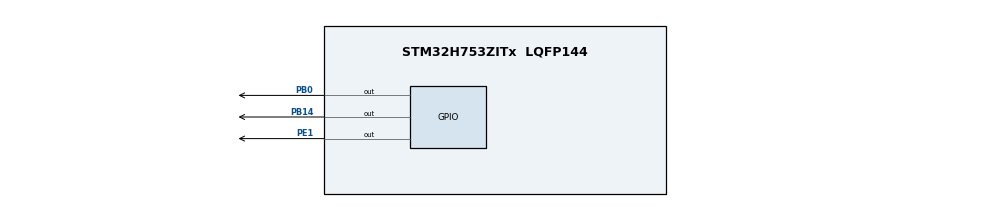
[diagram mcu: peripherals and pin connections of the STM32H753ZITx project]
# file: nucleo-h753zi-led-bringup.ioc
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CORTEX_M7.CPU_DCache=Disabled
CORTEX_M7.CPU_ICache=Disabled
CORTEX_M7.MPU_Control=__NULL
CORTEX_M7.default_mode_Activation=1
Mcu.Family=STM32H7
Mcu.Name=STM32H753ZITx
Mcu.Package=LQFP144
NVIC.PriorityGroup=NVIC_PRIORITYGROUP_4
PB0.Signal=GPIO_Output
PB14.Signal=GPIO_Output
PC14-OSC32_IN\ (OSC32_IN).Signal=RCC_OSC32_IN
PC15-OSC32_OUT\ (OSC32_OUT).Signal=RCC_OSC32_OUT
PD8.GPIO_Label=STLINK_RX
PD8.Signal=USART3_TX
PD9.GPIO_Label=STLINK_TX
PD9.Signal=USART3_RX
PE1.Signal=GPIO_Output
PH0-OSC_IN\ (PH0).Signal=RCC_OSC_IN
PH1-OSC_OUT\ (PH1).Signal=RCC_OSC_OUT
ProjectManager.HeapSize=0x200
ProjectManager.StackSize=0x400
ProjectManager.TargetToolchain=Makefile
RCC.ADCFreq_Value=129000000
RCC.APB1Freq_Value=64000000
RCC.APB2Freq_Value=64000000
RCC.APB3Freq_Value=64000000
RCC.APB4Freq_Value=64000000
RCC.CortexFreq_Value=64000000
RCC.DIVM1=1
RCC.DIVN1=24
RCC.DIVQ1=4
RCC.HCLKFreq_Value=64000000
RCC.HSE_VALUE=8000000
RCC.PLLFRACN=0
RCC.PWR_Regulator_Voltage_Scale=PWR_REGULATOR_VOLTAGE_SCALE2
RCC.SYSCLKFreq_VALUE=64000000
RCC.USBFreq_Value=384000000
board=NUCLEO-H753ZI

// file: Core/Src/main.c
/* USER CODE BEGIN Header */
/**
  ******************************************************************************
  * @file           : main.c
  * @brief          : Main program body
  ******************************************************************************
  * @attention
  *
  * Copyright (c) 2025 STMicroelectronics.
  * All rights reserved.
  *
  * This software is licensed under terms that can be found in the LICENSE file
  * in the root directory of this software component.
  * If no LICENSE file comes with this software, it is provided AS-IS.
  *
  ******************************************************************************
  */
/* USER CODE END Header */
#include "main.h"

void SystemClock_Config(void);
static void MX_GPIO_Init(void);

int main(void)
{

  /* MCU Configuration--------------------------------------------------------*/

  /* Reset of all peripherals, Initializes the Flash interface and the Systick. */
  HAL_Init();

  /* Configure the system clock */
  SystemClock_Config();

  /* Initialize all configured peripherals */
  MX_GPIO_Init();
  /* USER CODE BEGIN 2 */
  HAL_GPIO_WritePin(GPIOB, GPIO_PIN_0 | GPIO_PIN_14, GPIO_PIN_SET);
  HAL_GPIO_WritePin(GPIOE, GPIO_PIN_1, GPIO_PIN_SET);
  /* USER CODE END 2 */

  /* Infinite loop */
  while (1)
  {

  }
}

void SystemClock_Config(void)
{
  RCC_OscInitTypeDef RCC_OscInitStruct = {0};
  RCC_ClkInitTypeDef RCC_ClkInitStruct = {0};

  /** Supply configuration update enable
  */
  HAL_PWREx_ConfigSupply(PWR_LDO_SUPPLY);

  /** Configure the main internal regulator output voltage
  */
  __HAL_PWR_VOLTAGESCALING_CONFIG(PWR_REGULATOR_VOLTAGE_SCALE2);

  while(!__HAL_PWR_GET_FLAG(PWR_FLAG_VOSRDY)) {}

  /** Initializes the RCC Oscillators according to the specified parameters
  * in the RCC_OscInitTypeDef structure.
  */
  RCC_OscInitStruct.OscillatorType = RCC_OSCILLATORTYPE_HSI;
  RCC_OscInitStruct.HSIState = RCC_HSI_DIV1;
  RCC_OscInitStruct.HSICalibrationValue = RCC_HSICALIBRATION_DEFAULT;
  RCC_OscInitStruct.PLL.PLLState = RCC_PLL_NONE;
  if (HAL_RCC_OscConfig(&RCC_OscInitStruct) != HAL_OK)
  {
    Error_Handler();
  }

  /** Initializes the CPU, AHB and APB buses clocks
  */
  RCC_ClkInitStruct.ClockType = RCC_CLOCKTYPE_HCLK|RCC_CLOCKTYPE_SYSCLK
                              |RCC_CLOCKTYPE_PCLK1|RCC_CLOCKTYPE_PCLK2
                              |RCC_CLOCKTYPE_D3PCLK1|RCC_CLOCKTYPE_D1PCLK1;
  RCC_ClkInitStruct.SYSCLKSource = RCC_SYSCLKSOURCE_HSI;
  RCC_ClkInitStruct.SYSCLKDivider = RCC_SYSCLK_DIV1;
  RCC_ClkInitStruct.AHBCLKDivider = RCC_HCLK_DIV1;
  RCC_ClkInitStruct.APB3CLKDivider = RCC_APB3_DIV1;
  RCC_ClkInitStruct.APB1CLKDivider = RCC_APB1_DIV1;
  RCC_ClkInitStruct.APB2CLKDivider = RCC_APB2_DIV1;
  RCC_ClkInitStruct.APB4CLKDivider = RCC_APB4_DIV1;

  if (HAL_RCC_ClockConfig(&RCC_ClkInitStruct, FLASH_LATENCY_1) != HAL_OK)
  {
    Error_Handler();
  }
}

static void MX_GPIO_Init(void)
{
  GPIO_InitTypeDef GPIO_InitStruct = {0};

  /* GPIO Ports Clock Enable */
  __HAL_RCC_GPIOC_CLK_ENABLE();
  __HAL_RCC_GPIOH_CLK_ENABLE();
  __HAL_RCC_GPIOB_CLK_ENABLE();
  __HAL_RCC_GPIOE_CLK_ENABLE();

  /*Configure GPIO pin Output Level */
  HAL_GPIO_WritePin(GPIOB, GPIO_PIN_0|GPIO_PIN_14, GPIO_PIN_RESET);

  /*Configure GPIO pin Output Level */
  HAL_GPIO_WritePin(GPIOE, GPIO_PIN_1, GPIO_PIN_RESET);

  /*Configure GPIO pins : PB0 PB14 */
  GPIO_InitStruct.Pin = GPIO_PIN_0|GPIO_PIN_14;
  GPIO_InitStruct.Mode = GPIO_MODE_OUTPUT_PP;
  GPIO_InitStruct.Pull = GPIO_NOPULL;
  GPIO_InitStruct.Speed = GPIO_SPEED_FREQ_LOW;
  HAL_GPIO_Init(GPIOB, &GPIO_InitStruct);

  /*Configure GPIO pin : PE1 */
  GPIO_InitStruct.Pin = GPIO_PIN_1;
  GPIO_InitStruct.Mode = GPIO_MODE_OUTPUT_PP;
  GPIO_InitStruct.Pull = GPIO_NOPULL;
  GPIO_InitStruct.Speed = GPIO_SPEED_FREQ_LOW;
  HAL_GPIO_Init(GPIOE, &GPIO_InitStruct);

}

void Error_Handler(void)
{
  __disable_irq();
  while (1)
  {
  }
}
